# STM32L052 register map
File version: 1.0
CPU: CM0+ r0p0, little endian, MPU, no FPU, 4 interrupt priority bits
Registers are 32-bit, read-write, reset 0x0 unless marked. A register's access mark holds for its fields unless they carry their own. Offsets are from the block's base; [hi:lo] are bit positions.

## LPTIM — Low power timer
Base 0x40007C00
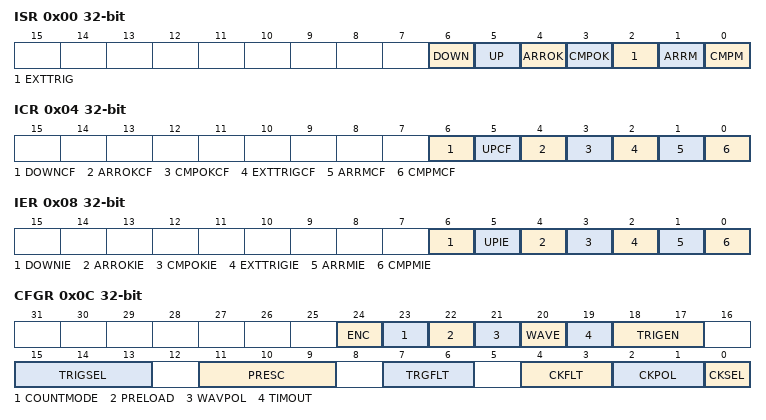
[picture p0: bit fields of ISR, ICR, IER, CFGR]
0x00 ISR ro — Interrupt and Status Register
  [6] DOWN — Counter direction change up to down
  [5] UP — Counter direction change down to up
  [4] ARROK — Autoreload register update OK
  [3] CMPOK — Compare register update OK
  [2] EXTTRIG — External trigger edge event
  [1] ARRM — Autoreload match
  [0] CMPM — Compare match
0x04 ICR wo — Interrupt Clear Register
  [6] DOWNCF — Direction change to down Clear Flag
  [5] UPCF — Direction change to UP Clear Flag
  [4] ARROKCF — Autoreload register update OK Clear Flag
  [3] CMPOKCF — Compare register update OK Clear Flag
  [2] EXTTRIGCF — External trigger valid edge Clear Flag
  [1] ARRMCF — Autoreload match Clear Flag
  [0] CMPMCF — compare match Clear Flag
0x08 IER — Interrupt Enable Register
  [6] DOWNIE — Direction change to down Interrupt Enable
  [5] UPIE — Direction change to UP Interrupt Enable
  [4] ARROKIE — Autoreload register update OK Interrupt Enable
  [3] CMPOKIE — Compare register update OK Interrupt Enable
  [2] EXTTRIGIE — External trigger valid edge Interrupt Enable
  [1] ARRMIE — Autoreload match Interrupt Enable
  [0] CMPMIE — Compare match Interrupt Enable
0x0C CFGR — Configuration Register
  [24] ENC — Encoder mode enable
  [23] COUNTMODE — counter mode enabled
  [22] PRELOAD — Registers update mode
  [21] WAVPOL — Waveform shape polarity
  [20] WAVE — Waveform shape
  [19] TIMOUT — Timeout enable
  [18:17] TRIGEN — Trigger enable and polarity
  [15:13] TRIGSEL — Trigger selector
  [11:9] PRESC — Clock prescaler
  [7:6] TRGFLT — Configurable digital filter for trigger
  [4:3] CKFLT — Configurable digital filter for external clock
  [2:1] CKPOL — Clock Polarity
  [0] CKSEL — Clock selector
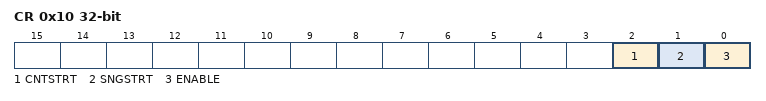
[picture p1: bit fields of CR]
0x10 CR — Control Register
  [2] CNTSTRT — Timer start in continuous mode
  [1] SNGSTRT — LPTIM start in single mode
  [0] ENABLE — LPTIM Enable
0x14 CMP — Compare Register
  [15:0] CMP — Compare value.
0x18 ARR reset 0x1 — Autoreload Register
  [15:0] ARR — Auto reload value.
0x1C CNT ro — Counter Register
  [15:0] CNT — Counter value.

## TIM6 — Basic-timers
Base 0x40001000
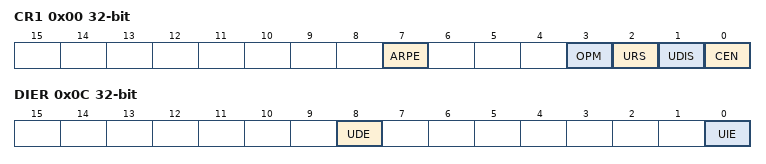
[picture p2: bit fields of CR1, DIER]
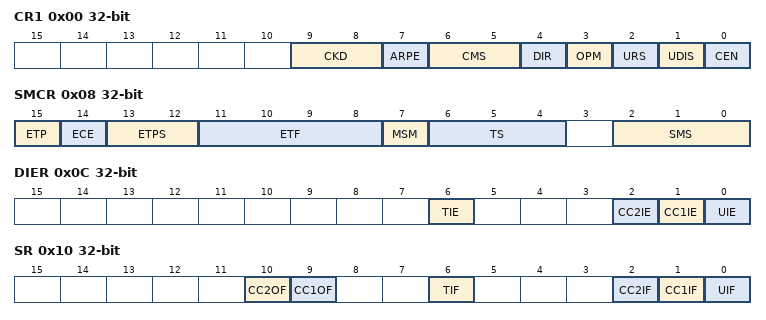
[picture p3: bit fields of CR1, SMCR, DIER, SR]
0x00 CR1 — control register 1
  [7] ARPE — Auto-reload preload enable
  [3] OPM — One-pulse mode
  [2] URS — Update request source
  [1] UDIS — Update disable
  [0] CEN — Counter enable
0x04 CR2 — control register 2
  [6:4] MMS — Master mode selection
0x0C DIER — DMA/Interrupt enable register
  [8] UDE — Update DMA request enable
  [0] UIE — Update interrupt enable
0x10 SR — status register
  [0] UIF — Update interrupt flag
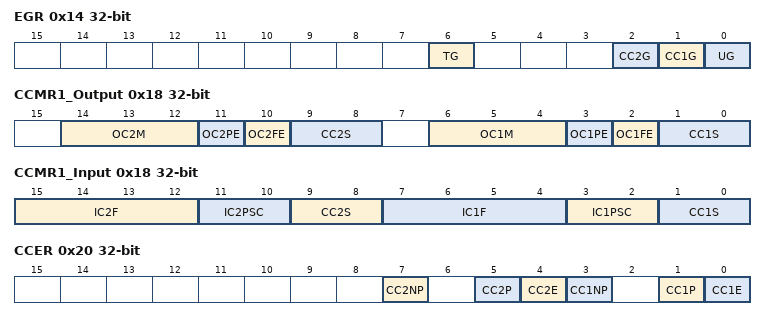
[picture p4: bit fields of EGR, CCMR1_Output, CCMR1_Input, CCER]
0x14 EGR wo — event generation register
  [0] UG — Update generation
0x24 CNT — counter
  [15:0] CNT — Low counter value
0x28 PSC — prescaler
  [15:0] PSC — Prescaler value
0x2C ARR — auto-reload register
  [15:0] ARR — Low Auto-reload value

## TIM21 — General-purpose-timers
Base 0x40010800
0x00 CR1 — control register 1
  [9:8] CKD — Clock division
  [7] ARPE — Auto-reload preload enable
  [6:5] CMS — Center-aligned mode selection
  [4] DIR — Direction
  [3] OPM — One-pulse mode
  [2] URS — Update request source
  [1] UDIS — Update disable
  [0] CEN — Counter enable
0x04 CR2 — control register 2
  [6:4] MMS — Master mode selection
0x08 SMCR — slave mode control register
  [15] ETP — External trigger polarity
  [14] ECE — External clock enable
  [13:12] ETPS — External trigger prescaler
  [11:8] ETF — External trigger filter
  [7] MSM — Master/Slave mode
  [6:4] TS — Trigger selection
  [2:0] SMS — Slave mode selection
0x0C DIER — DMA/Interrupt enable register
  [6] TIE — Trigger interrupt enable
  [2] CC2IE — Capture/Compare 2 interrupt enable
  [1] CC1IE — Capture/Compare 1 interrupt enable
  [0] UIE — Update interrupt enable
0x10 SR — status register
  [10] CC2OF — Capture/compare 2 overcapture flag
  [9] CC1OF — Capture/Compare 1 overcapture flag
  [6] TIF — Trigger interrupt flag
  [2] CC2IF — Capture/Compare 2 interrupt flag
  [1] CC1IF — Capture/compare 1 interrupt flag
  [0] UIF — Update interrupt flag
0x14 EGR wo — event generation register
  [6] TG — Trigger generation
  [2] CC2G — Capture/compare 2 generation
  [1] CC1G — Capture/compare 1 generation
  [0] UG — Update generation
0x18 CCMR1_Output — capture/compare mode register (output mode)
  [14:12] OC2M — Output Compare 2 mode
  [11] OC2PE — Output Compare 2 preload enable
  [10] OC2FE — Output Compare 2 fast enable
  [9:8] CC2S — Capture/Compare 2 selection
  [6:4] OC1M — Output Compare 1 mode
  [3] OC1PE — Output Compare 1 preload enable
  [2] OC1FE — Output Compare 1 fast enable
  [1:0] CC1S — Capture/Compare 1 selection
0x18 CCMR1_Input (alternate view of CCMR1_Output) — capture/compare mode register 1 (input mode)
  [15:12] IC2F — Input capture 2 filter
  [11:10] IC2PSC — Input capture 2 prescaler
  [9:8] CC2S — Capture/Compare 2 selection
  [7:4] IC1F — Input capture 1 filter
  [3:2] IC1PSC — Input capture 1 prescaler
  [1:0] CC1S — Capture/Compare 1 selection
0x20 CCER — capture/compare enable register
  [7] CC2NP — Capture/Compare 2 output Polarity
  [5] CC2P — Capture/Compare 2 output Polarity
  [4] CC2E — Capture/Compare 2 output enable
  [3] CC1NP — Capture/Compare 1 output Polarity
  [1] CC1P — Capture/Compare 1 output Polarity
  [0] CC1E — Capture/Compare 1 output enable
0x24 CNT — counter
  [15:0] CNT — counter value
0x28 PSC — prescaler
  [15:0] PSC — Prescaler value
0x2C ARR — auto-reload register
  [15:0] ARR — Auto-reload value
0x34 CCR1 — capture/compare register 1
  [15:0] CCR1 — Capture/Compare 1 value
0x38 CCR2 — capture/compare register 2
  [15:0] CCR2 — Capture/Compare 2 value
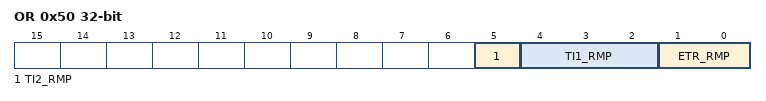
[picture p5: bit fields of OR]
0x50 OR — TIM21 option register
  [5] TI2_RMP — Timer21 TI2
  [4:2] TI1_RMP — Timer21 TI1
  [1:0] ETR_RMP — Timer21 ETR remap

## TIM22 — General-purpose-timers
Base 0x40011400
Registers as TIM21; these are added or differ:
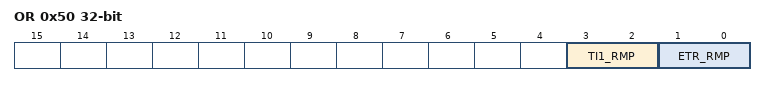
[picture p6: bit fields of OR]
0x50 OR — TIM22 option register
  [3:2] TI1_RMP — Timer22 TI1
  [1:0] ETR_RMP — Timer22 ETR remap
